# EMIF1 register map
Vendor: Texas Instruments
Registers are 32-bit, read-write, reset 0x0 unless marked. A register's access mark holds for its fields unless they carry their own. Offsets are as the file gives them; [hi:lo] are bit positions; {n}, {i} and the like mark numbered series.

## EMIF1 (part 2 of 2)
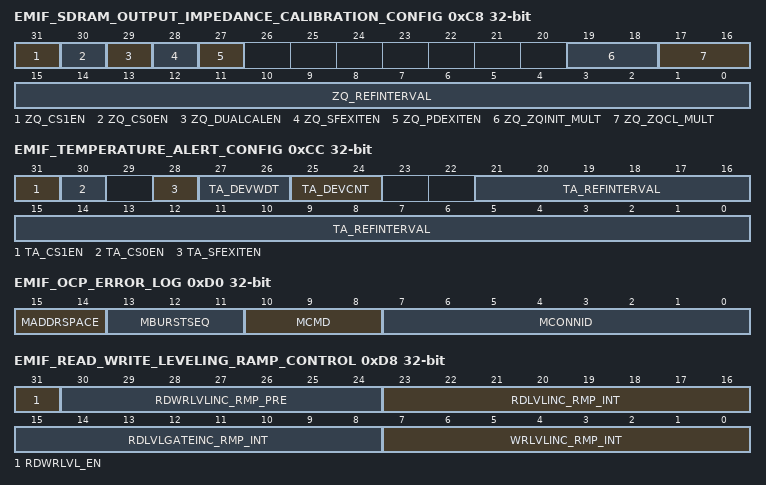
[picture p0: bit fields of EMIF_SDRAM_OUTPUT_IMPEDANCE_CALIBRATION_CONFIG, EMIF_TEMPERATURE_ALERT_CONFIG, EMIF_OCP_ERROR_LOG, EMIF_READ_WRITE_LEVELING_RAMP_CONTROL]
0xC8 EMIF_SDRAM_OUTPUT_IMPEDANCE_CALIBRATION_CONFIG access per field — SDRAM Output Impedance Calibration Config Register
  [31] ZQ_CS1EN rw — Writing a 1 enables ZQ calibration for CS1.
  [30] ZQ_CS0EN rw — Writing a 1 enables ZQ calibration for CS0.
  [29] ZQ_DUALCALEN rw — ZQ Dual Calibration enable. Allows both ranks to be ZQ calibrated simultaneously. Setting this bit requires both chip selects to have a separate calibration resistor per device.
  [28] ZQ_SFEXITEN rw — Writing a 1 enables the issuing of ZQCL on Self-Refresh exit.
  [27] ZQ_PDEXITEN rw — Writing a 1 enables the issuing of ZQCL on Active Power-Down, and Precharge Power-Down exit.
  [19:18] ZQ_ZQINIT_MULT rw — Indicates the number of ZQCL durations that make up a ZQINIT duration, minus one..
  [17:16] ZQ_ZQCL_MULT rw — Indicates the number of ZQCS intervals that make up a ZQCL duration, minus one. ZQCS interval is defined by ZQ_ZQCS inEMIF_SDRAM_TIMING_3.
  [15:0] ZQ_REFINTERVAL rw — Number of refresh periods between ZQCS commands. This field supports between one refresh period to 256 ms between ZQCS calibration commands. Refresh period is defined by refresh_rate inEMIF_SDRAM_REFRESH_CONTROL register.
0xCC EMIF_TEMPERATURE_ALERT_CONFIG access per field — Temperature Alert Config Register
  [31] TA_CS1EN rw — Writing a 1 enables temperature alert polling for CS1.
  [30] TA_CS0EN rw — Writing a 1 enables temperature alert polling for CS0.
  [28] TA_SFEXITEN rw — Temperature Alert Poll on Self-Refresh, Active Power-Down, and Precharge Power-Down exit enable. Writing a 1 enables the issuing of a temperature alert poll on Self-Refresh exit.
  [27:26] TA_DEVWDT rw — This field indicates how wide a physical device is. It is used in conjunction with the TA_DEVCNT field to determine which byte lanes contain the temperature alert info. A value of 0: 8-bit wide, 1: 16- bit wide, 2: 32-bit wide. All others are reserved. If this field is set to 1 and the TA_DEVCNT field is set to 1 the byte mask for checking will be 4'b0101.
  [25:24] TA_DEVCNT rw — This field indicates which external byte lanes contain a device for temperature monitoring. A value of 0 = one device, 1 = two devices, 2 = four devices. All other reserved.
  [21:0] TA_REFINTERVAL rw — Number of refresh periods between temperature alert polls. This field supports between one refresh period to 10 seconds between temperature alert polls. Refresh period is defined by REFRESH_RATE inEMIF_SDRAM_REFRESH_CONTROL register.
0xD0 EMIF_OCP_ERROR_LOG ro — OCP Error Log Register
  [15:14] MADDRSPACE — Address space of the first errored transaction. 0x0: SDRAM 0x1: Reserved for LPDDR2-NVM 0x2: Reserved 0x3: Internal registers
  [13:11] MBURSTSEQ — Addressing mode of the first errored transaction. (see, for more information)
  [10:8] MCMD — Command type of the first errored transaction. (see, for more information)
  [7:0] MCONNID — Connection ID of the first errored transaction.
0xD4 EMIF_READ_WRITE_LEVELING_RAMP_WINDOW access per field — Read/write leveling ramp window register
  [12:0] RDWRLVLINC_RMP_WIN rw — Incremental leveling ramp window in number of refresh periods. The value programmed is minus one the required value. Refresh period is defined by REFRESH_RATE inEMIF_SDRAM_REFRESH_CONTROL register.
0xD8 EMIF_READ_WRITE_LEVELING_RAMP_CONTROL — Read/write leveling ramp control register
  [31] RDWRLVL_EN — Read-Write Leveling enable. Set 1 to enable leveling. Set 0 to disable leveling.
  [30:24] RDWRLVLINC_RMP_PRE — Incremental leveling pre-scalar in number of refresh periods during ramp window. The value programmed is minus one the required value. Refresh period is defined by REFRESH_RATE inEMIF_SDRAM_REFRESH_CONTROL register.
  [23:16] RDLVLINC_RMP_INT — Incremental read data eye training interval during ramp window. Number of RDWRLVLINC_RMP_PRE intervals between incremental read data eye training during ramp window. A value of 0 will disable incremental read data eye training.
  [15:8] RDLVLGATEINC_RMP_INT — Incremental read DQS gate training interval during ramp window. Number of RDWRLVLINC_RMP_PRE intervals between incremental read DQS gate training during ramp window. A value of 0 will disable incremental read DQS gate training.
  [7:0] WRLVLINC_RMP_INT — Incremental write leveling interval during ramp window. Number of RDWRLVLINC_RMP_PRE intervals between incremental write leveling during ramp window. A value of 0 will disable incremental write leveling.
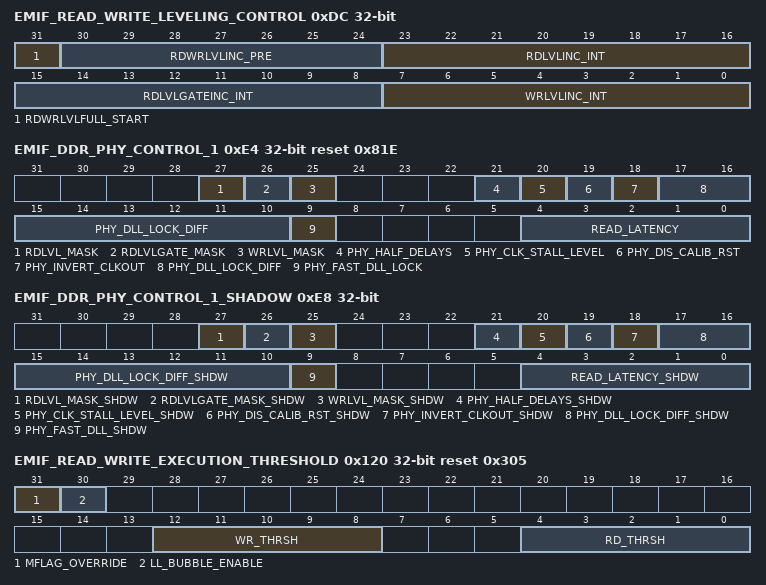
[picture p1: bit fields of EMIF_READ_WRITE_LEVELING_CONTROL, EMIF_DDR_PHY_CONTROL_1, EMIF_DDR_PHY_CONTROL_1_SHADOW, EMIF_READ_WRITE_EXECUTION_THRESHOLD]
0xDC EMIF_READ_WRITE_LEVELING_CONTROL — Read/write leveling control register
  [31] RDWRLVLFULL_START — Full leveling trigger. Writing a 1 to this field triggers full read and write leveling. This bit will self clear to 0.
  [30:24] RDWRLVLINC_PRE — Incremental leveling pre-scalar in number of refresh periods. The value programmed is minus one the required value. Refresh period is defined by REFRESH_RATE inEMIF_SDRAM_REFRESH_CONTROL register.
  [23:16] RDLVLINC_INT — Incremental read data eye training interval. Number of RDWRLVLINC_PRE intervals between incremental read data eye training. A value of 0 will disable incremental read data eye training.
  [15:8] RDLVLGATEINC_INT — Incremental read DQS gate training interval. Number of RDWRLVLINC_PRE intervals between incremental read DQS gate training. A value of 0 will disable incremental read DQS gate training.
  [7:0] WRLVLINC_INT — Incremental write leveling interval. Number of RDWRLVLINC_PRE intervals between incremental write leveling. A value of 0 will disable incremental write leveling.
0xE4 EMIF_DDR_PHY_CONTROL_1 reset 0x81E — PHY control register 1
  [27] RDLVL_MASK — Writing a 1 to this field will mask read data eye training during full leveling command, plus drives reg_phy_use_rd_data_eye_level control low to allow user to use programmed ratio values. Incremental training needs to be disabled using incremental training registers.
  [26] RDLVLGATE_MASK — Writing a 1 to this field will mask dqs gate training during full leveling command, plus drives reg_phy_use_rd_dqs_level control low to allow user to use programmed ratio values. Incremental training needs to be disabled using incremental training registers.
  [25] WRLVL_MASK — Writing a 1 to this field will mask write leveling training during full leveling command, plus drives reg_phy_use_wr_level control low to allow user to use programmed ratio values. Incremental training needs to be disabled using incremental training registers.
  [21] PHY_HALF_DELAYS — Adjust slave delay line delays to support 2× mode 1: 2× mode (MDLL clock is half the rate of PHY) - OPP_NOM 0: 1× mode ( MDLL clock rate is same as PHY) - OPP_BOOT
  [20] PHY_CLK_STALL_LEVEL — Enable variable idle value for delay lines. Enable during normal operations to avoid differential aging in the delay lines.
  [19] PHY_DIS_CALIB_RST — Disable the dll_calib (internally generated) signal from resetting the Read Capture FIFO pointers and portions of data PHYs. Debug only. Note: dll_calib is generated by 1. EMIF_MISC_REG[0] DLL_CALIB_OS set to 1,or 2. by the PHY when it detects that the clock frequency variation has exceeded the bounds set by PHY_DLL_LOCK_DIFF or 3. periodically throughout the leveling process.
  [18] PHY_INVERT_CLKOUT — Inverts the polarity of DRAM clock. This bit must be set to 0 when in LDDDR2 mode. 0: core clock is passed on to DRAM 1: inverted core clock is passed on to DRAM
  [17:10] PHY_DLL_LOCK_DIFF — The maximum number of delay line taps variation while maintaining the master DLL lock. When the PHY is in locked state and the variation on the clock exceeds the variation indicated by this field, the lock signal is de-asserted and a dll_calib signal is generated. To prevent the dll_calib signal from being asserted in the middle of traffic when the clock jitter exceeds the variation, this register needs to be set to a value which will ensure that the lock will not be lost. Recommended value is 16.
  [9] PHY_FAST_DLL_LOCK — Controls master DLL to lock fast or average logic must be part of locking process. Set to 1 before OPP transition commences, and set back to 0 after OPP transition completes. 1: MDLL lock is asserted based on single sample 0: MDLL lock is asserted based on average of 16 samples.
  [4:0] READ_LATENCY — This field defines the read latency for the read data from SDRAM in number of DDR clock cycles. This field is used by the EMIF as well as the PHY. READ_LATENCY = RL + reg_phy_rdc_we_to_re -1. EMIF uses above equation to calculate reg_phy_rdc_we_to_re and forward it to the PHY. For DDR3, the true RL is used, not the decoded value. See JEDEC spec. The write latency (WL) is tied to the RL for the LPDDR2. See the LPDDR2 SDRAM standard.
0xE8 EMIF_DDR_PHY_CONTROL_1_SHADOW
  [27] RDLVL_MASK_SHDW — Shadow field for RDLVL_MASK
  [26] RDLVLGATE_MASK_SHDW — Shadow field for RDLVLGATE_MASK
  [25] WRLVL_MASK_SHDW — Shadow field for WRLVL_MASK
  [21] PHY_HALF_DELAYS_SHDW — Shadow field for PHY_HALF_DELAYS
  [20] PHY_CLK_STALL_LEVEL_SHDW — Shadow field for PHY_CLK_STALL_LEVEL
  [19] PHY_DIS_CALIB_RST_SHDW — Shadow field for PHY_DIS_CALIB_RST
  [18] PHY_INVERT_CLKOUT_SHDW — Shadow field for PHY_INVERT_CLKOUT
  [17:10] PHY_DLL_LOCK_DIFF_SHDW — Shadow field for PHY_DLL_LOCK_DIFF
  [9] PHY_FAST_DLL_SHDW — Shadow field for PHY_FAST_DLL
  [4:0] READ_LATENCY_SHDW — Shadow field for READ_LATENCY
0x120 EMIF_READ_WRITE_EXECUTION_THRESHOLD access per field reset 0x305
  [31] MFLAG_OVERRIDE rw — Mflag override. When set to 1, forces Mflag internally to be zero (compatibility mode). : MFLAG_OVERRIDE must be considered a static control.
  [30] LL_BUBBLE_ENABLE rw — LL bubble enable. When set to 1, enables LL bubble function. Allows one access (one beat of burst), for any bank that is open. This gives performance improvement and avoids bank thrashing (in other words, have gone thru activation stage and should allow one access, even if higher priority LL port command comes thru)
  [12:8] WR_THRSH rw — Write Threshold. Number of SDRAM write bursts after which the EMIF arbitration will switch to executing read commands. The value programmed is always minus one the required number
  [4:0] RD_THRSH ro — Read threshold. Number of SDRAM read bursts after which the EMIF arbitration will switch to executing write commands. The value that is programmed is always minus one the required number
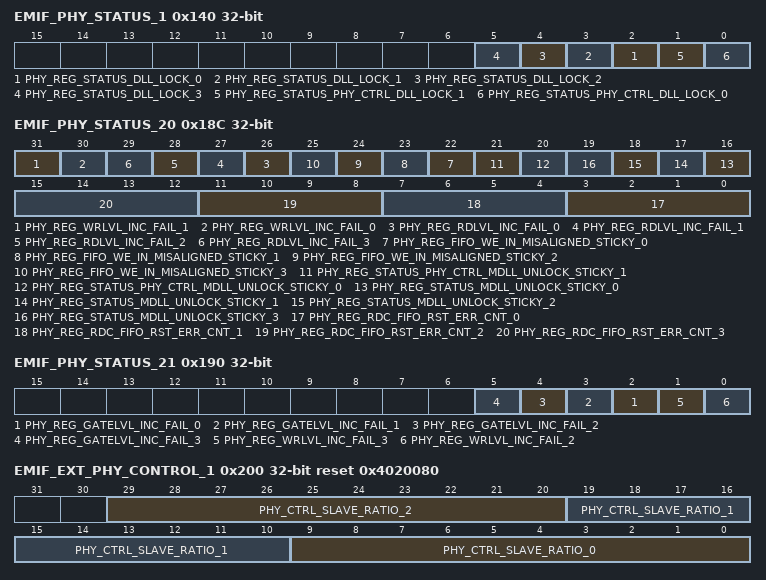
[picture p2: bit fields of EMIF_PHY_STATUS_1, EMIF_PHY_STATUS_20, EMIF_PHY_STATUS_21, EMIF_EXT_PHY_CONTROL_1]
0x140 EMIF_PHY_STATUS_1 ro
  [n+2] PHY_REG_STATUS_DLL_LOCK_{n} (n=0..3) — Reflects lock status of DLL of data PHY {n} 1: Master DLL is locked 0: Master DLL is not locked
  [1] PHY_REG_STATUS_PHY_CTRL_DLL_LOCK_1 — Reflects lock status of DLL 1 (command PHY 2) 1: Master DLL is locked 0: Master DLL is not locked
  [0] PHY_REG_STATUS_PHY_CTRL_DLL_LOCK_0 — Reflects lock status of DLL 0 (command PHY 0 and 1) 1: Master DLL is locked 0: Master DLL is not locked
0x18C EMIF_PHY_STATUS_20 ro
  [31] PHY_REG_WRLVL_INC_FAIL_1 — Incremental Write Leveling Fail Status Flag. Data PHY 1 1: Incremental read leveling test has failed. 0: Incremental read leveling test has passed.
  [30] PHY_REG_WRLVL_INC_FAIL_0 — Incremental Write Leveling Fail Status Flag. Data PHY 0 1: Incremental read leveling test has failed. 0: Incremental read leveling test has passed.
  [n+26] PHY_REG_RDLVL_INC_FAIL_{n} (n=0..3) — Incremental Read Leveling Fail Status Flag. Data PHY {n} 1: Incremental read leveling test has failed. 0: Incremental read leveling test has passed.
  [n+22] PHY_REG_FIFO_WE_IN_MISALIGNED_STICKY_{n} (n=0..3) — Data PHY {n} 1: fifo_we_in rising edge doesn't fall in pre-amble phase of dqs_in. Error case. 0: fifo_we_in rising edge falls in pre-amble phase of dqs_in. No error.
  [21] PHY_REG_STATUS_PHY_CTRL_MDLL_UNLOCK_STICKY_1 — Command DLL 1 (command PHY 2) 1: Master DLL has lost the lock 0: Master DLL never lost the lock
  [20] PHY_REG_STATUS_PHY_CTRL_MDLL_UNLOCK_STICKY_0 — Command DLL 0 (command PHYs 0 and 1) 1: Master DLL has lost the lock 0: Master DLL never lost the lock
  [n+16] PHY_REG_STATUS_MDLL_UNLOCK_STICKY_{n} (n=0..3) — Data PHY {n} 1: Master DLL has lost the lock 0: Master DLL never lost the lock
  [4n+3:4n] PHY_REG_RDC_FIFO_RST_ERR_CNT_{n} (n=0..3) — Counter for counting the number of times the pointers of read capture FIFO differ when they are reset by dll_calib. Data PHY {n}
0x190 EMIF_PHY_STATUS_21 ro
  [n+2] PHY_REG_GATELVL_INC_FAIL_{n} (n=0..3) — Incremental Gate Leveling Fail Status Flag. Data PHY {n} 1: Incremental gate leveling test has failed. 0: Incremental gate leveling test has passed.
  [1] PHY_REG_WRLVL_INC_FAIL_3 — Incremental Write Leveling Fail Status Flag. Data PHY 3 1: Incremental read leveling test has failed. 0: Incremental read leveling test has passed.
  [0] PHY_REG_WRLVL_INC_FAIL_2 — Incremental Write Leveling Fail Status Flag. Data PHY 2 1: Incremental read leveling test has failed. 0: Incremental read leveling test has passed.
0x200 EMIF_EXT_PHY_CONTROL_1 reset 0x4020080 — Programs command PHY slave DLL ratio. Ratio value for address/command launch timing in command PHYs. 0x80: 50% (180°), 0x40: 25% (90°)
  [29:20] PHY_CTRL_SLAVE_RATIO_2 — Slave DLL ratio for command PHY 2
  [19:10] PHY_CTRL_SLAVE_RATIO_1 — Slave DLL ratio for command PHY 1. In DDR3 mode, set to 0x100 (100%) if inverted clock is used (EMIF_DDR_PHY_CONTROL_1[18] PHY_INVERT_CLKOUT = 1).
  [9:0] PHY_CTRL_SLAVE_RATIO_0 — Slave DLL ratio for command PHY 0. In DDR3 mode, set to 0x100 (100%) if inverted clock is used (EMIF_DDR_PHY_CONTROL_1[18] PHY_INVERT_CLKOUT = 1).
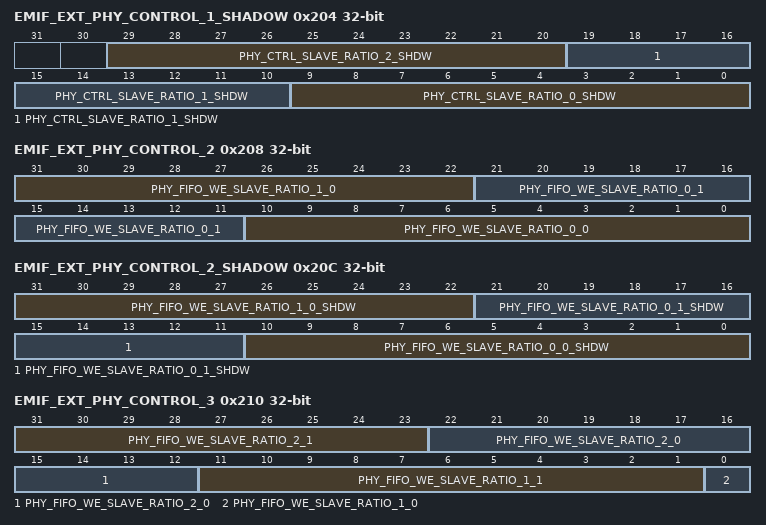
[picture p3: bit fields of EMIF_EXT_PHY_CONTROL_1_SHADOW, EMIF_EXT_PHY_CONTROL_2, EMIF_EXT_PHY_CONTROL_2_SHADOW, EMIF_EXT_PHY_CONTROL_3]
0x204 EMIF_EXT_PHY_CONTROL_1_SHADOW
  [29:20] PHY_CTRL_SLAVE_RATIO_2_SHDW — Shadow field for PHY_CTRL_SLAVE_RATIO_2
  [19:10] PHY_CTRL_SLAVE_RATIO_1_SHDW — Shadow field for PHY_CTRL_SLAVE_RATIO_1
  [9:0] PHY_CTRL_SLAVE_RATIO_0_SHDW — Shadow field for PHY_CTRL_SLAVE_RATIO_0
0x208 EMIF_EXT_PHY_CONTROL_2 — DQS gate opening delay. Set to 0x0B7 for each PHY/Rank.
  [31:22] PHY_FIFO_WE_SLAVE_RATIO_1_0 — DQS gate opening delay[9:0] for Data PHY 1, Rank 0
  [21:11] PHY_FIFO_WE_SLAVE_RATIO_0_1 — DQS gate opening delay[10:0] for Data PHY 0, Rank 1
  [10:0] PHY_FIFO_WE_SLAVE_RATIO_0_0 — DQS gate opening delay[10:0] for Data PHY 0, Rank 0
0x20C EMIF_EXT_PHY_CONTROL_2_SHADOW
  [31:22] PHY_FIFO_WE_SLAVE_RATIO_1_0_SHDW — Shadow field for PHY_FIFO_WE_SLAVE_RATIO_1_0
  [21:11] PHY_FIFO_WE_SLAVE_RATIO_0_1_SHDW — Shadow field for PHY_FIFO_WE_SLAVE_RATIO_0_1
  [10:0] PHY_FIFO_WE_SLAVE_RATIO_0_0_SHDW — Shadow field for PHY_FIFO_WE_SLAVE_RATIO_0_0
0x210 EMIF_EXT_PHY_CONTROL_3 — DQS gate opening delay. Set to 0x0B7 for each PHY/Rank.
  [31:23] PHY_FIFO_WE_SLAVE_RATIO_2_1 — DQS gate opening delay[8:0] for Data PHY 2, Rank 1
  [22:12] PHY_FIFO_WE_SLAVE_RATIO_2_0 — DQS gate opening delay[10:0] for Data PHY 2, Rank 0
  [11:1] PHY_FIFO_WE_SLAVE_RATIO_1_1 — DQS gate opening delay[10:0] for Data PHY 1, Rank 1
  [0] PHY_FIFO_WE_SLAVE_RATIO_1_0 — DQS gate opening delay[10] for Data PHY 1, Rank 0
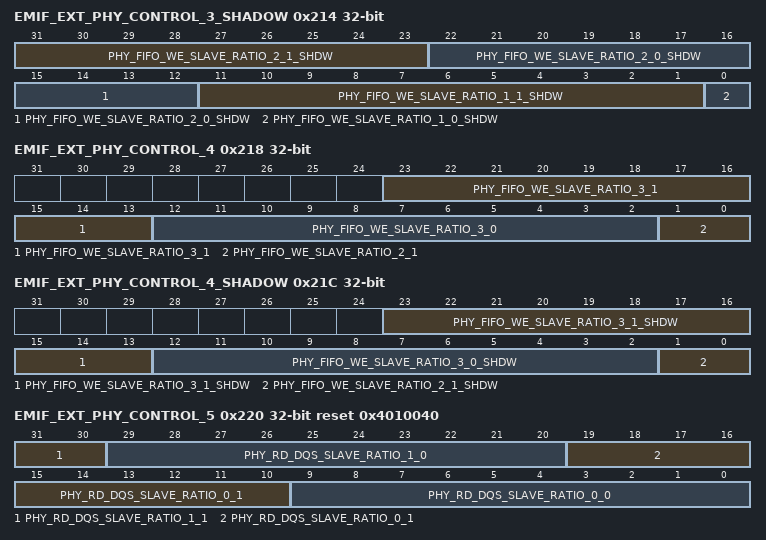
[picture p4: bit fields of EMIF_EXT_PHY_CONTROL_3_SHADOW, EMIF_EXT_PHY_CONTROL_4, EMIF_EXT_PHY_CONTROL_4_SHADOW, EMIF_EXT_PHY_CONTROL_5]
0x214 EMIF_EXT_PHY_CONTROL_3_SHADOW
  [31:23] PHY_FIFO_WE_SLAVE_RATIO_2_1_SHDW — Shadow field for PHY_FIFO_WE_SLAVE_RATIO_2_1
  [22:12] PHY_FIFO_WE_SLAVE_RATIO_2_0_SHDW — Shadow field for PHY_FIFO_WE_SLAVE_RATIO_2_0
  [11:1] PHY_FIFO_WE_SLAVE_RATIO_1_1_SHDW — Shadow field for PHY_FIFO_WE_SLAVE_RATIO_1_1
  [0] PHY_FIFO_WE_SLAVE_RATIO_1_0_SHDW — Shadow field for PHY_FIFO_WE_SLAVE_RATIO_1_0
0x218 EMIF_EXT_PHY_CONTROL_4 — DQS gate opening delay. Set to 0x0B7 for each PHY/Rank.
  [23:13] PHY_FIFO_WE_SLAVE_RATIO_3_1 — DQS gate opening delay[10:0] for Data PHY 3, Rank 1
  [12:2] PHY_FIFO_WE_SLAVE_RATIO_3_0 — DQS gate opening delay[10:0] for Data PHY 3, Rank 0
  [1:0] PHY_FIFO_WE_SLAVE_RATIO_2_1 — DQS gate opening delay[10:9] for Data PHY 2, Rank 1
0x21C EMIF_EXT_PHY_CONTROL_4_SHADOW
  [23:13] PHY_FIFO_WE_SLAVE_RATIO_3_1_SHDW — Shadow field for PHY_FIFO_WE_SLAVE_RATIO_3_1
  [12:2] PHY_FIFO_WE_SLAVE_RATIO_3_0_SHDW — Shadow field for PHY_FIFO_WE_SLAVE_RATIO_3_0
  [1:0] PHY_FIFO_WE_SLAVE_RATIO_2_1_SHDW — Shadow field for PHY_FIFO_WE_SLAVE_RATIO_2_1
0x220 EMIF_EXT_PHY_CONTROL_5 reset 0x4010040 — Ratio value for read DQS slave DLL. Do not change. This is a fixed value in LPDDR2 mode, and a don't care in DDR3 mode due to the training.
  [31:30] PHY_RD_DQS_SLAVE_RATIO_1_1 — Ratio value for read DQS slave DLL.[1:0] for Data PHY 1, Rank 1
  [29:20] PHY_RD_DQS_SLAVE_RATIO_1_0 — Ratio value for read DQS slave DLL.[9:0] for Data PHY 1, Rank 0
  [19:10] PHY_RD_DQS_SLAVE_RATIO_0_1 — Ratio value for read DQS slave DLL.[9:0] for Data PHY 0, Rank 1
  [9:0] PHY_RD_DQS_SLAVE_RATIO_0_0 — Ratio value for read DQS slave DLL.[9:0] for Data PHY 0, Rank 0
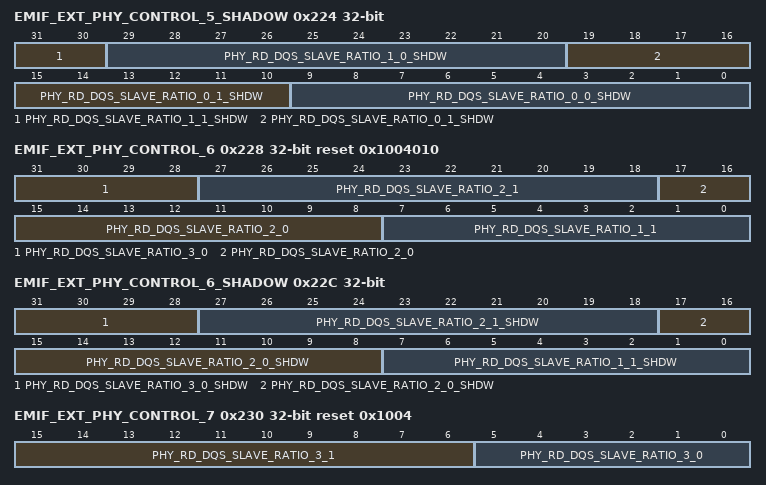
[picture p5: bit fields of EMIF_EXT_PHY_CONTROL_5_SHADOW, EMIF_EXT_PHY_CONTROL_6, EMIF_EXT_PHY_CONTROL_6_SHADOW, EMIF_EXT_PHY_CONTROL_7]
0x224 EMIF_EXT_PHY_CONTROL_5_SHADOW
  [31:30] PHY_RD_DQS_SLAVE_RATIO_1_1_SHDW — Shadow field for PHY_RD_DQS_SLAVE_RATIO_1_1
  [29:20] PHY_RD_DQS_SLAVE_RATIO_1_0_SHDW — Shadow field for PHY_RD_DQS_SLAVE_RATIO_1_0
  [19:10] PHY_RD_DQS_SLAVE_RATIO_0_1_SHDW — Shadow field for PHY_RD_DQS_SLAVE_RATIO_0_1
  [9:0] PHY_RD_DQS_SLAVE_RATIO_0_0_SHDW — Shadow field for PHY_RD_DQS_SLAVE_RATIO_0_0
0x228 EMIF_EXT_PHY_CONTROL_6 reset 0x1004010 — Ratio value for read DQS slave DLL. Do not change. This is a fixed value in LPDDR2 mode, and a don't care in DDR3 mode due to the training.
  [31:28] PHY_RD_DQS_SLAVE_RATIO_3_0 — Ratio value for read DQS slave DLL.[3:0] for Data PHY 3, Rank 0
  [27:18] PHY_RD_DQS_SLAVE_RATIO_2_1 — Ratio value for read DQS slave DLL.[9:0] for Data PHY 2, Rank 1
  [17:8] PHY_RD_DQS_SLAVE_RATIO_2_0 — Ratio value for read DQS slave DLL.[9:0] for Data PHY 2, Rank 0
  [7:0] PHY_RD_DQS_SLAVE_RATIO_1_1 — Ratio value for read DQS slave DLL.[9:2] for Data PHY 1, Rank 1
0x22C EMIF_EXT_PHY_CONTROL_6_SHADOW
  [31:28] PHY_RD_DQS_SLAVE_RATIO_3_0_SHDW — Shadow field for PHY_RD_DQS_SLAVE_RATIO_3_0
  [27:18] PHY_RD_DQS_SLAVE_RATIO_2_1_SHDW — Shadow field for PHY_RD_DQS_SLAVE_RATIO_2_1
  [17:8] PHY_RD_DQS_SLAVE_RATIO_2_0_SHDW — Shadow field for PHY_RD_DQS_SLAVE_RATIO_2_0
  [7:0] PHY_RD_DQS_SLAVE_RATIO_1_1_SHDW — Shadow field for PHY_RD_DQS_SLAVE_RATIO_1_1
0x230 EMIF_EXT_PHY_CONTROL_7 reset 0x1004 — Ratio value for read DQS slave DLL. Do not change. This is a fixed value in LPDDR2 mode, and a don't care in DDR3 mode due to the training.
  [15:6] PHY_RD_DQS_SLAVE_RATIO_3_1 — Ratio value for read DQS slave DLL.[9:0] for Data PHY 3, Rank 1
  [5:0] PHY_RD_DQS_SLAVE_RATIO_3_0 — Ratio value for read DQS slave DLL.[9:4] for Data PHY 3, Rank 0
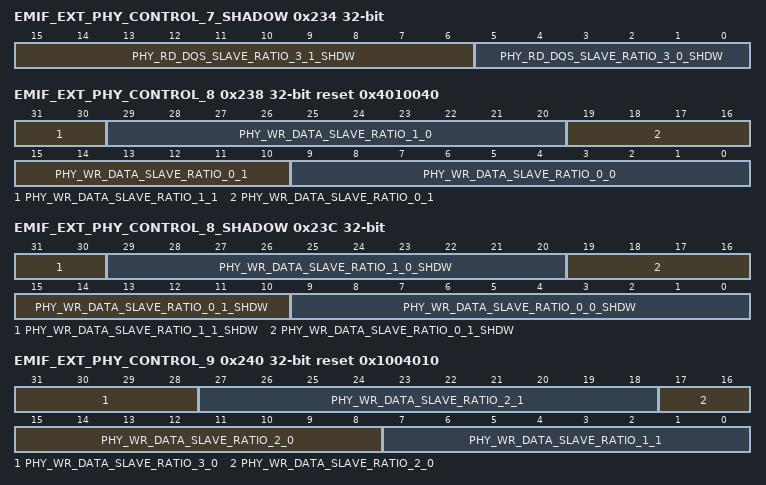
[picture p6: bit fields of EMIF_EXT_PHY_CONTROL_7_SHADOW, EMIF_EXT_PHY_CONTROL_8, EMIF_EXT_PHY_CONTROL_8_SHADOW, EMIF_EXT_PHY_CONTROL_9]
0x234 EMIF_EXT_PHY_CONTROL_7_SHADOW
  [15:6] PHY_RD_DQS_SLAVE_RATIO_3_1_SHDW — Shadow field for PHY_RD_DQS_SLAVE_RATIO_3_1
  [5:0] PHY_RD_DQS_SLAVE_RATIO_3_0_SHDW — Shadow field for PHY_RD_DQS_SLAVE_RATIO_3_0
0x238 EMIF_EXT_PHY_CONTROL_8 reset 0x4010040 — Ratio value for write data slave DLL. Do not change. This is a fixed value in LPDDR2 mode, and a don't care in DDR3 mode due to the training.
  [31:30] PHY_WR_DATA_SLAVE_RATIO_1_1 — Ratio value for write data slave DLL.[1:0] for Data PHY 1, Rank 1
  [29:20] PHY_WR_DATA_SLAVE_RATIO_1_0 — Ratio value for write data slave DLL.[9:0] for Data PHY 1, Rank 0
  [19:10] PHY_WR_DATA_SLAVE_RATIO_0_1 — Ratio value for write data slave DLL.[9:0] for Data PHY 0, Rank 1
  [9:0] PHY_WR_DATA_SLAVE_RATIO_0_0 — Ratio value for write data slave DLL.[9:0] for Data PHY 0, Rank 0
0x23C EMIF_EXT_PHY_CONTROL_8_SHADOW
  [31:30] PHY_WR_DATA_SLAVE_RATIO_1_1_SHDW — Shadow field for PHY_WR_DATA_SLAVE_RATIO_1_1
  [29:20] PHY_WR_DATA_SLAVE_RATIO_1_0_SHDW — Shadow field for PHY_WR_DATA_SLAVE_RATIO_1_0
  [19:10] PHY_WR_DATA_SLAVE_RATIO_0_1_SHDW — Shadow field for PHY_WR_DATA_SLAVE_RATIO_0_1
  [9:0] PHY_WR_DATA_SLAVE_RATIO_0_0_SHDW — Shadow field for PHY_WR_DATA_SLAVE_RATIO_0_0
0x240 EMIF_EXT_PHY_CONTROL_9 reset 0x1004010 — Ratio value for write data slave DLL. Do not change. This is a fixed value in LPDDR2 mode, and a don't care in DDR3 mode due to the training.
  [31:28] PHY_WR_DATA_SLAVE_RATIO_3_0 — Ratio value for write data slave DLL.[3:0] for Data PHY 3, Rank 0
  [27:18] PHY_WR_DATA_SLAVE_RATIO_2_1 — Ratio value for write data slave DLL.[9:0] for Data PHY 2, Rank 1
  [17:8] PHY_WR_DATA_SLAVE_RATIO_2_0 — Ratio value for write data slave DLL.[9:0] for Data PHY 2, Rank 0
  [7:0] PHY_WR_DATA_SLAVE_RATIO_1_1 — Ratio value for write data slave DLL.[9:2] for Data PHY 1, Rank 1
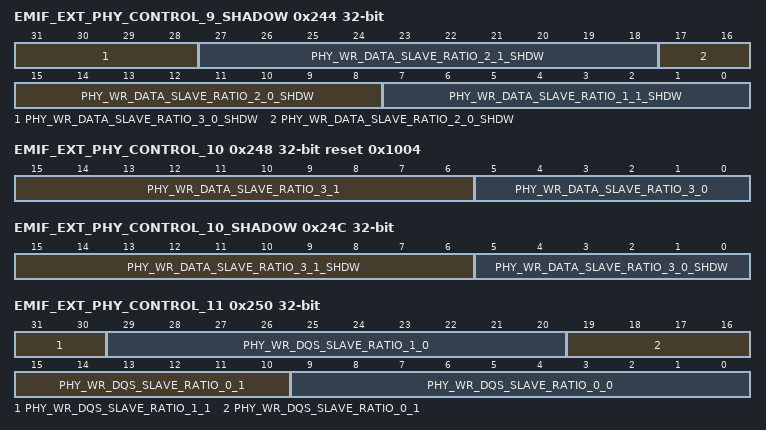
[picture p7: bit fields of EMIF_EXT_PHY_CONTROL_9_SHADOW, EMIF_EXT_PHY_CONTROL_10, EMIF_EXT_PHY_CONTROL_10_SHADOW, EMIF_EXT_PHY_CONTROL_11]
0x244 EMIF_EXT_PHY_CONTROL_9_SHADOW
  [31:28] PHY_WR_DATA_SLAVE_RATIO_3_0_SHDW — Shadow field for PHY_WR_DATA_SLAVE_RATIO_3_0
  [27:18] PHY_WR_DATA_SLAVE_RATIO_2_1_SHDW — Shadow field for PHY_WR_DATA_SLAVE_RATIO_2_1
  [17:8] PHY_WR_DATA_SLAVE_RATIO_2_0_SHDW — Shadow field for PHY_WR_DATA_SLAVE_RATIO_2_0
  [7:0] PHY_WR_DATA_SLAVE_RATIO_1_1_SHDW — Shadow field for PHY_WR_DATA_SLAVE_RATIO_1_1
0x248 EMIF_EXT_PHY_CONTROL_10 reset 0x1004 — Ratio value for write data slave DLL. Do not change. This is a fixed value in LPDDR2 mode, and a don't care in DDR3 mode due to the training.
  [15:6] PHY_WR_DATA_SLAVE_RATIO_3_1 — Ratio value for write data slave DLL.[9:0] for Data PHY 3, Rank 1
  [5:0] PHY_WR_DATA_SLAVE_RATIO_3_0 — Ratio value for write data slave DLL.[9:4] for Data PHY 3, Rank 0
0x24C EMIF_EXT_PHY_CONTROL_10_SHADOW
  [15:6] PHY_WR_DATA_SLAVE_RATIO_3_1_SHDW — Shadow field for PHY_WR_DATA_SLAVE_RATIO_3_1
  [5:0] PHY_WR_DATA_SLAVE_RATIO_3_0_SHDW — Shadow field for PHY_WR_DATA_SLAVE_RATIO_3_0
0x250 EMIF_EXT_PHY_CONTROL_11 — Ratio value for write DQS slave DLL. Do not change. This is a fixed value in LPDDR2 mode, and a don't care in DDR3 mode due to the training.
  [31:30] PHY_WR_DQS_SLAVE_RATIO_1_1 — Ratio value for write DQS slave DLL.[1:0] for Data PHY 1, Rank 1
  [29:20] PHY_WR_DQS_SLAVE_RATIO_1_0 — Ratio value for write DQS slave DLL.[9:0] for Data PHY 1, Rank 0
  [19:10] PHY_WR_DQS_SLAVE_RATIO_0_1 — Ratio value for write DQS slave DLL.[9:0] for Data PHY 0, Rank 1
  [9:0] PHY_WR_DQS_SLAVE_RATIO_0_0 — Ratio value for write DQS slave DLL.[9:0] for Data PHY 0, Rank 0
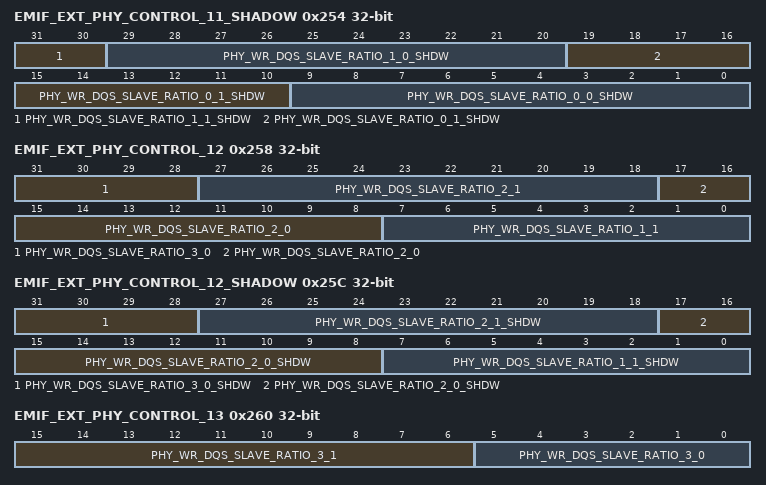
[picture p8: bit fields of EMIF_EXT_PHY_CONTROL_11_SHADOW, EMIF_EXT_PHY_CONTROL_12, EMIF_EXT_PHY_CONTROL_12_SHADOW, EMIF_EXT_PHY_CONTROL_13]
0x254 EMIF_EXT_PHY_CONTROL_11_SHADOW
  [31:30] PHY_WR_DQS_SLAVE_RATIO_1_1_SHDW — Shadow field for PHY_WR_DQS_SLAVE_RATIO_1_1
  [29:20] PHY_WR_DQS_SLAVE_RATIO_1_0_SHDW — Shadow field for PHY_WR_DQS_SLAVE_RATIO_1_0
  [19:10] PHY_WR_DQS_SLAVE_RATIO_0_1_SHDW — Shadow field for PHY_WR_DQS_SLAVE_RATIO_0_1
  [9:0] PHY_WR_DQS_SLAVE_RATIO_0_0_SHDW — Shadow field for PHY_WR_DQS_SLAVE_RATIO_0_0
0x258 EMIF_EXT_PHY_CONTROL_12 — Ratio value for write DQS slave DLL. Do not change. This is a fixed value in LPDDR2 mode, and a don't care in DDR3 mode due to the training.
  [31:28] PHY_WR_DQS_SLAVE_RATIO_3_0 — Ratio value for write DQS slave DLL.[3:0] for Data PHY 3, Rank 0
  [27:18] PHY_WR_DQS_SLAVE_RATIO_2_1 — Ratio value for write DQS slave DLL.[9:0] for Data PHY 2, Rank 1
  [17:8] PHY_WR_DQS_SLAVE_RATIO_2_0 — Ratio value for write DQS slave DLL.[9:0] for Data PHY 2, Rank 0
  [7:0] PHY_WR_DQS_SLAVE_RATIO_1_1 — Ratio value for write DQS slave DLL.[9:2] for Data PHY 1, Rank 1
0x25C EMIF_EXT_PHY_CONTROL_12_SHADOW
  [31:28] PHY_WR_DQS_SLAVE_RATIO_3_0_SHDW — Shadow field for PHY_WR_DQS_SLAVE_RATIO_3_0
  [27:18] PHY_WR_DQS_SLAVE_RATIO_2_1_SHDW — Shadow field for PHY_WR_DQS_SLAVE_RATIO_2_1
  [17:8] PHY_WR_DQS_SLAVE_RATIO_2_0_SHDW — Shadow field for PHY_WR_DQS_SLAVE_RATIO_2_0
  [7:0] PHY_WR_DQS_SLAVE_RATIO_1_1_SHDW — Shadow field for PHY_WR_DQS_SLAVE_RATIO_1_1
0x260 EMIF_EXT_PHY_CONTROL_13 — Ratio value for write DQS slave DLL. Do not change. This is a fixed value in LPDDR2 mode, and a don't care in DDR3 mode due to the training.
  [15:6] PHY_WR_DQS_SLAVE_RATIO_3_1 — Ratio value for write DQS slave DLL.[9:0] for Data PHY 3, Rank 1
  [5:0] PHY_WR_DQS_SLAVE_RATIO_3_0 — Ratio value for write DQS slave DLL.[9:4] for Data PHY 3, Rank 0
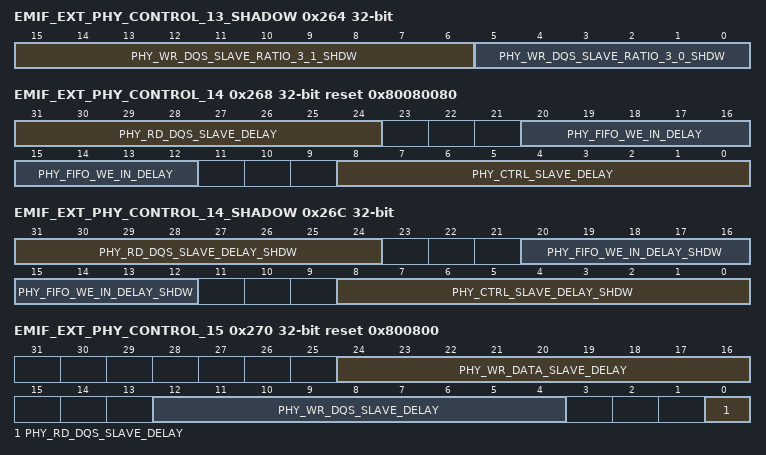
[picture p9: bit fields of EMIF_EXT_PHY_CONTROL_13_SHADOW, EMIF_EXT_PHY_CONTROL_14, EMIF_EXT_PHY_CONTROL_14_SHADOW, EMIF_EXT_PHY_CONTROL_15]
0x264 EMIF_EXT_PHY_CONTROL_13_SHADOW
  [15:6] PHY_WR_DQS_SLAVE_RATIO_3_1_SHDW — Shadow field for PHY_WR_DQS_SLAVE_RATIO_3_1
  [5:0] PHY_WR_DQS_SLAVE_RATIO_3_0_SHDW — Shadow field for PHY_WR_DQS_SLAVE_RATIO_3_0
0x268 EMIF_EXT_PHY_CONTROL_14 reset 0x80080080 — Only relevant when using the DLL in unlocked mode.
  [31:24] PHY_RD_DQS_SLAVE_DELAY — Replace delay/tap value for read DQS slave DLL with this value. Broadcast to all Ranks, all data PHYs, bits [7:0]
  [20:12] PHY_FIFO_WE_IN_DELAY — Replace delay/tap value for slave DLL with this value. Broadcast to all Ranks, all data PHYs
  [8:0] PHY_CTRL_SLAVE_DELAY — Replace delay/tap value for address/command timing slave DLL with this value. Broadcast to Command PHYs 2,1, and 0.
0x26C EMIF_EXT_PHY_CONTROL_14_SHADOW
  [31:24] PHY_RD_DQS_SLAVE_DELAY_SHDW — Shadow field for PHY_RD_DQS_SLAVE_DELAY
  [20:12] PHY_FIFO_WE_IN_DELAY_SHDW — Shadow field for PHY_FIFO_WE_IN_DELAY
  [8:0] PHY_CTRL_SLAVE_DELAY_SHDW — Shadow field for PHY_CTRL_SLAVE_DELAY
0x270 EMIF_EXT_PHY_CONTROL_15 reset 0x800800 — Only relevant when using the DLL in unlocked mode.
  [24:16] PHY_WR_DATA_SLAVE_DELAY — Replace delay/tap value for write data slave DLL with this value. Broadcast to all Ranks, all data PHYs
  [12:4] PHY_WR_DQS_SLAVE_DELAY — Replace delay/tap value for write DQS slave DLL with this value. Broadcast to all Ranks, all data PHYs
  [0] PHY_RD_DQS_SLAVE_DELAY — Replace delay/tap value for read DQS slave DLL with this value. Broadcast to all Ranks, all data PHYs, bit 8
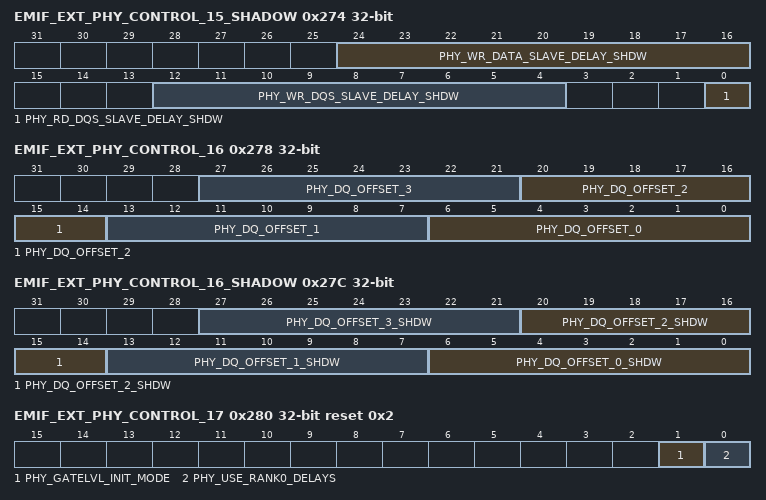
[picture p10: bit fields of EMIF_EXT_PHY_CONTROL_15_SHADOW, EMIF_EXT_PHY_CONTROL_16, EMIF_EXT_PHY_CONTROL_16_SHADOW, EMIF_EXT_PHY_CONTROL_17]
0x274 EMIF_EXT_PHY_CONTROL_15_SHADOW
  [24:16] PHY_WR_DATA_SLAVE_DELAY_SHDW — Shadow field for PHY_WR_DATA_SLAVE_DELAY
  [12:4] PHY_WR_DQS_SLAVE_DELAY_SHDW — Shadow field for PHY_WR_DQS_SLAVE_DELAY
  [0] PHY_RD_DQS_SLAVE_DELAY_SHDW — Shadow field for PHY_RD_DQS_SLAVE_DELAY
0x278 EMIF_EXT_PHY_CONTROL_16 — Offset value from write dqs to write dq during write leveling. Set to 0x40 in LPDDR2 mode. Don't care in DDR3 mode due to the leveling.
  [7n+6:7n] PHY_DQ_OFFSET_{n} (n=0..3) — Offset value from write dqs to write dq during write leveling. Data PHY {n}
0x27C EMIF_EXT_PHY_CONTROL_16_SHADOW
  [7n+6:7n] PHY_DQ_OFFSET_{n}_SHDW (n=0..3) — Shadow field for PHY_DQ_OFFSET_{n}
0x280 EMIF_EXT_PHY_CONTROL_17 reset 0x2
  [1] PHY_GATELVL_INIT_MODE — The user programmable init ratio selection mode. This bit must be 1 when in LPDDR2 mode. 1: selects a starting ratio value based on PHY_GATELVL_INIT_RATIO fields. 0: selects a starting ratio value based on Write Leveling of the same data PHY. This mode is only supported when write leveling has been run before gate leveling.
  [0] PHY_USE_RANK0_DELAYS — Delay selection. Must be set to 1 for LPDDR2, not recommended in DDR3 mode. 1: Rank 0 delays are used for both ranks during read/write. 0: Each Rank uses its own delay.
{0x1FC+8i} EMIF_EXT_PHY_CONTROL_{i}_SHADOW (i=17..23)
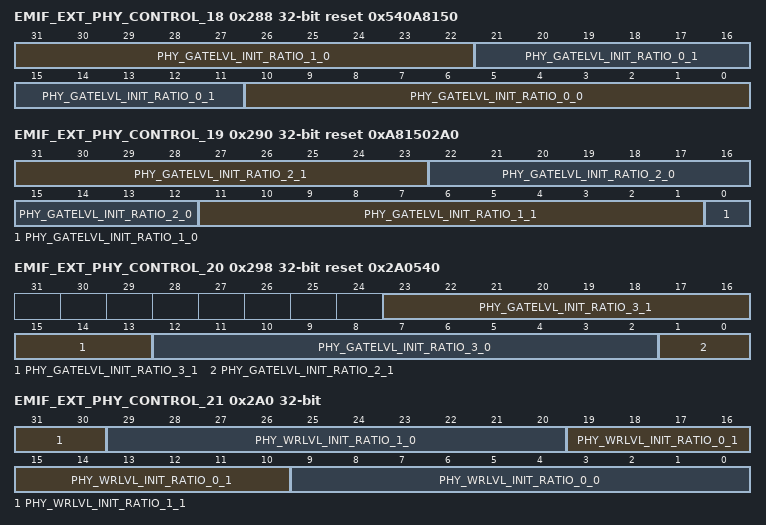
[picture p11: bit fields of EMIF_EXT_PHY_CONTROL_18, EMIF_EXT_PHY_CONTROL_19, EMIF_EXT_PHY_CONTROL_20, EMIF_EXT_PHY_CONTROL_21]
0x288 EMIF_EXT_PHY_CONTROL_18 reset 0x540A8150 — DQS gate training starting ratio. The recommended setting of PHY_GATELVL_INIT_RATIO is half cycle less than total delay required on fifo_we_in to align to DQS at PHY.
  [31:22] PHY_GATELVL_INIT_RATIO_1_0 — DQS gate training starting ratio[9:0] for Data PHY 1, Rank 0
  [21:11] PHY_GATELVL_INIT_RATIO_0_1 — DQS gate training starting ratio[10:0] for Data PHY 0, Rank 1
  [10:0] PHY_GATELVL_INIT_RATIO_0_0 — DQS gate training starting ratio[10:0] for Data PHY 0, Rank 0
0x290 EMIF_EXT_PHY_CONTROL_19 reset 0xA81502A0 — DQS gate training starting ratio. The recommended setting of PHY_GATELVL_INIT_RATIO is half cycle less than total delay required on fifo_we_in to align to DQS at PHY.
  [31:23] PHY_GATELVL_INIT_RATIO_2_1 — DQS gate training starting ratio[8:0] for Data PHY 2, Rank 1
  [22:12] PHY_GATELVL_INIT_RATIO_2_0 — DQS gate training starting ratio[10:0] for Data PHY 2, Rank 0
  [11:1] PHY_GATELVL_INIT_RATIO_1_1 — DQS gate training starting ratio[10:0] for Data PHY 1, Rank 1
  [0] PHY_GATELVL_INIT_RATIO_1_0 — DQS gate training starting ratio[10] for Data PHY 1, Rank 0
0x298 EMIF_EXT_PHY_CONTROL_20 reset 0x2A0540 — DQS gate training starting ratio. The recommended setting of PHY_GATELVL_INIT_RATIO is half cycle less than total delay required on fifo_we_in to align to DQS at PHY.
  [23:13] PHY_GATELVL_INIT_RATIO_3_1 — DQS gate training starting ratio[10:0] for Data PHY 3, Rank 1
  [12:2] PHY_GATELVL_INIT_RATIO_3_0 — DQS gate training starting ratio[10:0] for Data PHY 3, Rank 0
  [1:0] PHY_GATELVL_INIT_RATIO_2_1 — DQS gate training starting ratio[10:9] for Data PHY 2, Rank 1
0x2A0 EMIF_EXT_PHY_CONTROL_21 — Write leveling starting ratio. The recommended setting of PHY_WRLVL_INIT_RATIO is half cycle less than total skew between CLK and DQS at the DDR.
  [31:30] PHY_WRLVL_INIT_RATIO_1_1 — Write leveling starting ratio[1:0] for Data PHY 1, Rank 1
  [29:20] PHY_WRLVL_INIT_RATIO_1_0 — Write leveling starting ratio[9:0] for Data PHY 1, Rank 0
  [19:10] PHY_WRLVL_INIT_RATIO_0_1 — Write leveling starting ratio[9:0] for Data PHY 0, Rank 1
  [9:0] PHY_WRLVL_INIT_RATIO_0_0 — Write leveling starting ratio[9:0] for Data PHY 0, Rank 0
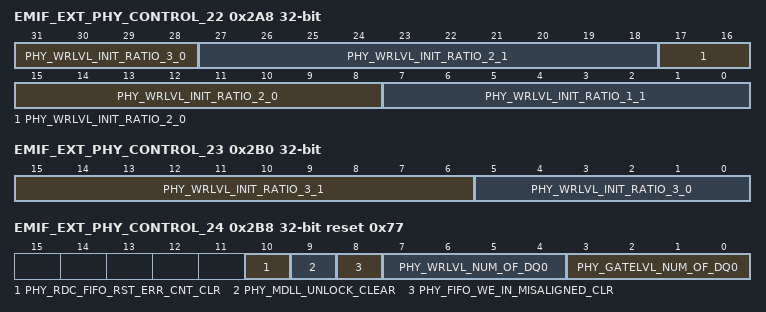
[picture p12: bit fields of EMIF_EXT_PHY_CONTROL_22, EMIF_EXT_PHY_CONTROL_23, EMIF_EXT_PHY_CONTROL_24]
0x2A8 EMIF_EXT_PHY_CONTROL_22 — Write leveling starting ratio. The recommended setting of PHY_WRLVL_INIT_RATIO is half cycle less than total skew between CLK and DQS at the DDR.
  [31:28] PHY_WRLVL_INIT_RATIO_3_0 — Write leveling starting ratio[3:0] for Data PHY 3, Rank 0
  [27:18] PHY_WRLVL_INIT_RATIO_2_1 — Write leveling starting ratio[9:0] for Data PHY 2, Rank 1
  [17:8] PHY_WRLVL_INIT_RATIO_2_0 — Write leveling starting ratio[9:0] for Data PHY 2, Rank 0
  [7:0] PHY_WRLVL_INIT_RATIO_1_1 — Write leveling starting ratio[9:2] for Data PHY 1, Rank 1
0x2B0 EMIF_EXT_PHY_CONTROL_23 — Write leveling starting ratio. The recommended setting of PHY_WRLVL_INIT_RATIO is half cycle less than total skew between CLK and DQS at the DDR.
  [15:6] PHY_WRLVL_INIT_RATIO_3_1 — Write leveling starting ratio[9:0] for Data PHY 3, Rank 1
  [5:0] PHY_WRLVL_INIT_RATIO_3_0 — Write leveling starting ratio[9:4] for Data PHY 3, Rank 0
0x2B8 EMIF_EXT_PHY_CONTROL_24 reset 0x77
  [10] PHY_RDC_FIFO_RST_ERR_CNT_CLR — Clear/reset theEMIF_PHY_STATUS_20[15:0] PHY_REG_RDC_FIFO_RST_ERR_CNT_0, EMIF_PHY_STATUS_5[11:0] PHY_REG_RDFIFO_RDPTR_*, and EMIF_PHY_STATUS_5[27:16] PHY_REG_RDFIFO_WRPTR_* status fields and flags. 0: no effect 1: clear
  [9] PHY_MDLL_UNLOCK_CLEAR — Clears theEMIF_PHY_STATUS_20[19:16] PHY_REG_STATUS_MDLL_UNLOCK_STICKY_* status flags. 0: no effect 1: clear
  [8] PHY_FIFO_WE_IN_MISALIGNED_CLR — Clears the forEMIF_PHY_STATUS_20[25:20] PHY_REG_FIFO_WE_IN_MISALIGNED_STICKY_* status flags. 0: no effect 1: clear
  [7:4] PHY_WRLVL_NUM_OF_DQ0 — This bit field determines the number of samples for dq0_in for each ratio increment by the write leveling FSM. Num_of_iteration = PHY_WRLVL_NUM_OF_DQ0 + 1. The minimum value supported is 3. Default setting of 7 is recommended.
  [3:0] PHY_GATELVL_NUM_OF_DQ0 — This bit field determines the number of samples for dq0_in for each ratio increment by the Gate Training FSM. Num_of_iteration = PHY_GATELVL_NUM_OF_DQ0 + 1. In LPDDR2 mode, the minimum value supported is 7. The overall minimum value supported is 3. Default setting of 7 is recommended.
0x2BC EMIF_EXT_PHY_CONTROL_24_SHADOW
  [3:0] PHY_GATELVL_NUM_OF_DQ0_SHDW — Shadow field for PHY_GATELVL_NUM_OF_DQ0
